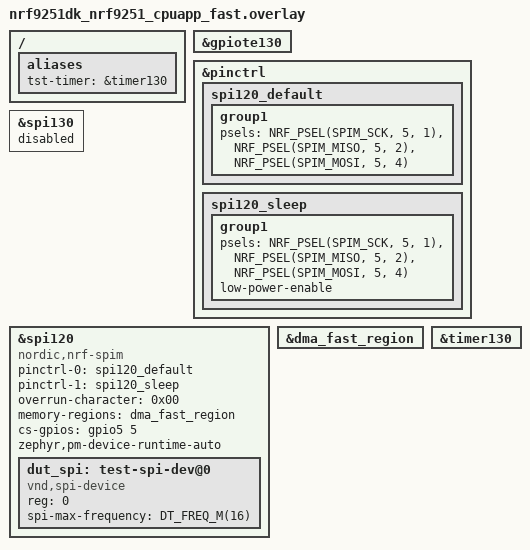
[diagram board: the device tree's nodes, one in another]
/*
 * Copyright (c) 2026 Nordic Semiconductor ASA
 *
 * SPDX-License-Identifier: LicenseRef-Nordic-5-Clause
 */

/* Required loopbacks:
 * P5.02 <-> P5.04
 */

/ {
	aliases {
		tst-timer = &timer130;
	};
};

&gpiote130 {
	status = "okay";
};

&pinctrl {
	spi120_default: spi120_default {
		group1 {
			psels = <NRF_PSEL(SPIM_SCK, 5, 1)>,
				<NRF_PSEL(SPIM_MISO, 5, 2)>,
				<NRF_PSEL(SPIM_MOSI, 5, 4)>;
		};
	};

	spi120_sleep: spi120_sleep {
		group1 {
			psels = <NRF_PSEL(SPIM_SCK, 5, 1)>,
				<NRF_PSEL(SPIM_MISO, 5, 2)>,
				<NRF_PSEL(SPIM_MOSI, 5, 4)>;
			low-power-enable;
		};
	};
};

&spi130 {
	status = "disabled";
	/delete-property/ dut_spi_dt;
};

&spi120 {
	compatible = "nordic,nrf-spim";
	status = "okay";
	pinctrl-0 = <&spi120_default>;
	pinctrl-1 = <&spi120_sleep>;
	pinctrl-names = "default", "sleep";
	overrun-character = <0x00>;
	memory-regions = <&dma_fast_region>;
	cs-gpios = <&gpio5 5 GPIO_ACTIVE_HIGH>;
	zephyr,pm-device-runtime-auto;

	dut_spi: test-spi-dev@0 {
		compatible = "vnd,spi-device";
		reg = <0>;
		spi-max-frequency = <DT_FREQ_M(16)>;
	};
};

&dma_fast_region {
	status = "okay";
};

/* Disable EXMIF node if it's added to the board definition later. */

&timer130 {
	status = "okay";
};
